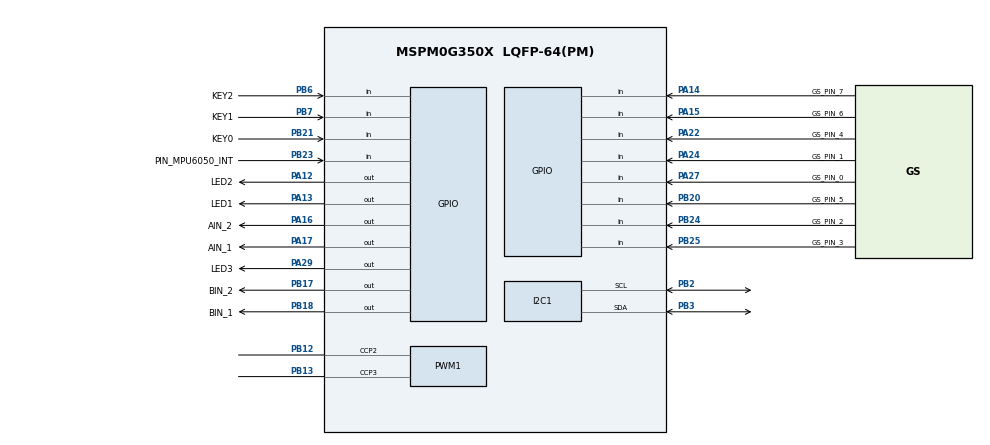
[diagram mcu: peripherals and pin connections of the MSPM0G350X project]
/**
 * @cliArgs --device "MSPM0G350X" --part "Default" --package "LQFP-64(PM)" --product "mspm0_sdk@2.05.01.01"
 * @versions {"tool":"1.24.0+4110"}
 */

/**
 * Import the modules used in this configuration.
 */
const Board         = scripting.addModule("/ti/driverlib/Board");
const GPIO          = scripting.addModule("/ti/driverlib/GPIO", {}, false);
const GPIO1         = GPIO.addInstance();
const GPIO2         = GPIO.addInstance();
const GPIO3         = GPIO.addInstance();
const GPIO4         = GPIO.addInstance();
const GPIO5         = GPIO.addInstance();
const GPIO6         = GPIO.addInstance();
const GPIO7         = GPIO.addInstance();
const I2C           = scripting.addModule("/ti/driverlib/I2C", {}, false);
const I2C1          = I2C.addInstance();
const PWM           = scripting.addModule("/ti/driverlib/PWM", {}, false);
const PWM1          = PWM.addInstance();
const QEI           = scripting.addModule("/ti/driverlib/QEI", {}, false);
const QEI1          = QEI.addInstance();
const SYSCTL        = scripting.addModule("/ti/driverlib/SYSCTL");
const ProjectConfig = scripting.addModule("/ti/project_config/ProjectConfig");

/**
 * Write custom configuration values to the imported modules.
 */
const divider7       = system.clockTree["PLL_PDIV"];
divider7.divideValue = 2;

const divider9       = system.clockTree["UDIV"];
divider9.divideValue = 2;

const multiplier2         = system.clockTree["PLL_QDIV"];
multiplier2.multiplyValue = 5;

const mux8       = system.clockTree["HSCLKMUX"];
mux8.inputSelect = "HSCLKMUX_SYSPLL2X";


GPIO1.$name                         = "OLED_GPIO_GRP";
GPIO1.port                          = "PORTB";
GPIO1.associatedPins.create(5);
GPIO1.associatedPins[0].$name       = "OLED_D0";
GPIO1.associatedPins[0].ioStructure = "SD";
GPIO1.associatedPins[0].assignedPin = "9";
GPIO1.associatedPins[1].$name       = "OLED_D1";
GPIO1.associatedPins[1].ioStructure = "SD";
GPIO1.associatedPins[1].assignedPin = "8";
GPIO1.associatedPins[2].$name       = "OLED_RES";
GPIO1.associatedPins[2].ioStructure = "SD";
GPIO1.associatedPins[2].assignedPin = "10";
GPIO1.associatedPins[3].$name       = "OLED_DC";
GPIO1.associatedPins[3].assignedPin = "11";
GPIO1.associatedPins[3].ioStructure = "SD";
GPIO1.associatedPins[4].$name       = "OLED_CS";
GPIO1.associatedPins[4].assignedPin = "14";
GPIO1.associatedPins[4].ioStructure = "SD";

GPIO2.$name                              = "GRAY_SENSOR_GRP";
GPIO2.associatedPins.create(8);
GPIO2.associatedPins[0].$name            = "GS_PIN_0";
GPIO2.associatedPins[0].direction        = "INPUT";
GPIO2.associatedPins[0].ioStructure      = "SD";
GPIO2.associatedPins[0].internalResistor = "PULL_DOWN";
GPIO2.associatedPins[0].pin.$assign      = "PA27";
GPIO2.associatedPins[1].$name            = "GS_PIN_1";
GPIO2.associatedPins[1].direction        = "INPUT";
GPIO2.associatedPins[1].ioStructure      = "SD";
GPIO2.associatedPins[1].internalResistor = "PULL_DOWN";
GPIO2.associatedPins[1].pin.$assign      = "PA24";
GPIO2.associatedPins[2].$name            = "GS_PIN_2";
GPIO2.associatedPins[2].direction        = "INPUT";
GPIO2.associatedPins[2].ioStructure      = "SD";
GPIO2.associatedPins[2].internalResistor = "PULL_DOWN";
GPIO2.associatedPins[2].pin.$assign      = "PB24";
GPIO2.associatedPins[3].$name            = "GS_PIN_3";
GPIO2.associatedPins[3].direction        = "INPUT";
GPIO2.associatedPins[3].ioStructure      = "SD";
GPIO2.associatedPins[3].internalResistor = "PULL_DOWN";
GPIO2.associatedPins[3].pin.$assign      = "PB25";
GPIO2.associatedPins[4].$name            = "GS_PIN_4";
GPIO2.associatedPins[4].direction        = "INPUT";
GPIO2.associatedPins[4].ioStructure      = "SD";
GPIO2.associatedPins[4].internalResistor = "PULL_DOWN";
GPIO2.associatedPins[4].pin.$assign      = "PA22";
GPIO2.associatedPins[5].$name            = "GS_PIN_5";
GPIO2.associatedPins[5].direction        = "INPUT";
GPIO2.associatedPins[5].ioStructure      = "SD";
GPIO2.associatedPins[5].internalResistor = "PULL_DOWN";
GPIO2.associatedPins[5].pin.$assign      = "PB20";
GPIO2.associatedPins[6].$name            = "GS_PIN_6";
GPIO2.associatedPins[6].direction        = "INPUT";
GPIO2.associatedPins[6].internalResistor = "PULL_DOWN";
GPIO2.associatedPins[6].pin.$assign      = "PA15";
GPIO2.associatedPins[7].$name            = "GS_PIN_7";
GPIO2.associatedPins[7].direction        = "INPUT";
GPIO2.associatedPins[7].internalResistor = "PULL_DOWN";
GPIO2.associatedPins[7].pin.$assign      = "PA14";

GPIO3.$name                          = "LED_GRP";
GPIO3.associatedPins.create(4);
GPIO3.associatedPins[0].assignedPort = "PORTB";
GPIO3.associatedPins[0].assignedPin  = "22";
GPIO3.associatedPins[0].$name        = "LED_G";
GPIO3.associatedPins[1].$name        = "LED1";
GPIO3.associatedPins[1].pin.$assign  = "PA13";
GPIO3.associatedPins[2].$name        = "LED2";
GPIO3.associatedPins[2].pin.$assign  = "PA12";
GPIO3.associatedPins[3].$name        = "LED3";
GPIO3.associatedPins[3].pin.$assign  = "PA29";

GPIO4.$name                               = "KEY_GRP";
GPIO4.associatedPins.create(3);
GPIO4.associatedPins[0].assignedPort      = "PORTB";
GPIO4.associatedPins[0].direction         = "INPUT";
GPIO4.associatedPins[0].ioStructure       = "SD";
GPIO4.associatedPins[0].internalResistor  = "PULL_UP";
GPIO4.associatedPins[0].interruptEn       = true;
GPIO4.associatedPins[0].polarity          = "RISE";
GPIO4.associatedPins[0].$name             = "KEY0";
GPIO4.associatedPins[0].pin.$assign       = "PB21";
GPIO4.associatedPins[1].$name             = "KEY1";
GPIO4.associatedPins[1].direction         = "INPUT";
GPIO4.associatedPins[1].ioStructure       = "SD";
GPIO4.associatedPins[1].interruptEn       = true;
GPIO4.associatedPins[1].polarity          = "FALL";
GPIO4.associatedPins[1].interruptPriority = "2";
GPIO4.associatedPins[1].internalResistor  = "PULL_UP";
GPIO4.associatedPins[1].inputFilter       = "8_CYCLES";
GPIO4.associatedPins[1].pin.$assign       = "PB7";
GPIO4.associatedPins[2].$name             = "KEY2";
GPIO4.associatedPins[2].direction         = "INPUT";
GPIO4.associatedPins[2].ioStructure       = "SD";
GPIO4.associatedPins[2].interruptEn       = true;
GPIO4.associatedPins[2].interruptPriority = "2";
GPIO4.associatedPins[2].polarity          = "FALL";
GPIO4.associatedPins[2].internalResistor  = "PULL_UP";
GPIO4.associatedPins[2].inputFilter       = "8_CYCLES";
GPIO4.associatedPins[2].pin.$assign       = "PB6";

GPIO5.$name                         = "MOTORA_GRP";
GPIO5.port                          = "PORTA";
GPIO5.associatedPins.create(2);
GPIO5.associatedPins[0].$name       = "AIN_1";
GPIO5.associatedPins[0].pin.$assign = "PA17";
GPIO5.associatedPins[1].$name       = "AIN_2";
GPIO5.associatedPins[1].ioStructure = "SD";
GPIO5.associatedPins[1].pin.$assign = "PA16";

GPIO6.$name                         = "MOTORB_GRP";
GPIO6.port                          = "PORTB";
GPIO6.associatedPins.create(2);
GPIO6.associatedPins[0].ioStructure = "SD";
GPIO6.associatedPins[0].$name       = "BIN_1";
GPIO6.associatedPins[0].pin.$assign = "PB18";
GPIO6.associatedPins[1].$name       = "BIN_2";
GPIO6.associatedPins[1].ioStructure = "SD";
GPIO6.associatedPins[1].pin.$assign = "PB17";

GPIO7.$name                               = "GPIO_MPU6050";
GPIO7.associatedPins[0].direction         = "INPUT";
GPIO7.associatedPins[0].$name             = "PIN_MPU6050_INT";
GPIO7.associatedPins[0].internalResistor  = "PULL_UP";
GPIO7.associatedPins[0].interruptEn       = true;
GPIO7.associatedPins[0].interruptPriority = "1";
GPIO7.associatedPins[0].polarity          = "FALL";
GPIO7.associatedPins[0].pin.$assign       = "PB23";

I2C1.$name                             = "I2C_MPU6050";
I2C1.basicEnableController             = true;
I2C1.basicControllerStandardBusSpeed   = "Fast";
I2C1.peripheral.sdaPin.$assign         = "PB3";
I2C1.peripheral.sclPin.$assign         = "PB2";
I2C1.sdaPinConfig.hideOutputInversion  = scripting.forceWrite(false);
I2C1.sdaPinConfig.onlyInternalResistor = scripting.forceWrite(false);
I2C1.sdaPinConfig.passedPeripheralType = scripting.forceWrite("Digital");
I2C1.sdaPinConfig.$name                = "ti_driverlib_gpio_GPIOPinGeneric10";
I2C1.sclPinConfig.hideOutputInversion  = scripting.forceWrite(false);
I2C1.sclPinConfig.onlyInternalResistor = scripting.forceWrite(false);
I2C1.sclPinConfig.passedPeripheralType = scripting.forceWrite("Digital");
I2C1.sclPinConfig.$name                = "ti_driverlib_gpio_GPIOPinGeneric13";

PWM1.pwmMode                    = "EDGE_ALIGN_UP";
PWM1.clockDivider               = 2;
PWM1.$name                      = "MOTOR_PWM";
PWM1.timerCount                 = 10000;
PWM1.ccIndex                    = [2,3];
PWM1.timerStartTimer            = true;
PWM1.ccIndexCmpl                = [2,3];
PWM1.PWM_CHANNEL_2.$name        = "ti_driverlib_pwm_PWMTimerCC0";
PWM1.PWM_CHANNEL_3.$name        = "ti_driverlib_pwm_PWMTimerCC1";
PWM1.ccp2PinConfig.$name        = "ti_driverlib_gpio_GPIOPinGeneric0";
PWM1.ccp3PinConfig.$name        = "ti_driverlib_gpio_GPIOPinGeneric1";
PWM1.peripheral.$assign         = "TIMA0";
PWM1.peripheral.ccp2Pin.$assign = "PB12";
PWM1.peripheral.ccp3Pin.$assign = "PB13";
PWM1.ccp2Pin_cmplConfig.$name   = "ti_driverlib_gpio_GPIOPinGeneric2";
PWM1.ccp3Pin_cmplConfig.$name   = "ti_driverlib_gpio_GPIOPinGeneric3";

QEI1.$name                              = "ENCODER_QEI";
QEI1.interrupts                         = ["ZERO_EVENT"];
QEI1.interruptPriority                  = "2";
QEI1.clockDivider                       = 4;
QEI1.loadValue                          = 8000;
QEI1.ccp0PinConfig.hideOutputInversion  = scripting.forceWrite(false);
QEI1.ccp0PinConfig.onlyInternalResistor = scripting.forceWrite(false);
QEI1.ccp0PinConfig.passedPeripheralType = scripting.forceWrite("Digital");
QEI1.ccp0PinConfig.$name                = "ti_driverlib_gpio_GPIOPinGeneric11";
QEI1.ccp1PinConfig.hideOutputInversion  = scripting.forceWrite(false);
QEI1.ccp1PinConfig.onlyInternalResistor = scripting.forceWrite(false);
QEI1.ccp1PinConfig.passedPeripheralType = scripting.forceWrite("Digital");
QEI1.ccp1PinConfig.$name                = "ti_driverlib_gpio_GPIOPinGeneric12";

SYSCTL.clockTreeEn           = true;
SYSCTL.forceDefaultClkConfig = true;
scripting.suppress("For best practices when the CPUCLK is running at 32MHz and above, clear the flash status bit using DL_FlashCTL_executeClearStatus\\(\\) before executing any flash operation\\. Otherwise there may be false positives\\.", SYSCTL);

ProjectConfig.genLibDL = false;
scripting.suppress("Driverlib inclusion is required for most use cases\\. Disable with caution\\.", ProjectConfig, "genLibDL");

/**
 * Pinmux solution for unlocked pins/peripherals. This ensures that minor changes to the automatic solver in a future
 * version of the tool will not impact the pinmux you originally saw.  These lines can be completely deleted in order to
 * re-solve from scratch.
 */
Board.peripheral.$suggestSolution             = "DEBUGSS";
Board.peripheral.swclkPin.$suggestSolution    = "PA20";
Board.peripheral.swdioPin.$suggestSolution    = "PA19";
GPIO1.associatedPins[0].pin.$suggestSolution  = "PB9";
GPIO1.associatedPins[1].pin.$suggestSolution  = "PB8";
GPIO1.associatedPins[2].pin.$suggestSolution  = "PB10";
GPIO1.associatedPins[3].pin.$suggestSolution  = "PB11";
GPIO1.associatedPins[4].pin.$suggestSolution  = "PB14";
GPIO3.associatedPins[0].pin.$suggestSolution  = "PB22";
I2C1.peripheral.$suggestSolution              = "I2C1";
PWM1.peripheral.ccp2Pin_cmpl.$suggestSolution = "PA11";
PWM1.peripheral.ccp3Pin_cmpl.$suggestSolution = "PA18";
QEI1.peripheral.$suggestSolution              = "TIMG8";
QEI1.peripheral.ccp0Pin.$suggestSolution      = "PA1";
QEI1.peripheral.ccp1Pin.$suggestSolution      = "PA0";
